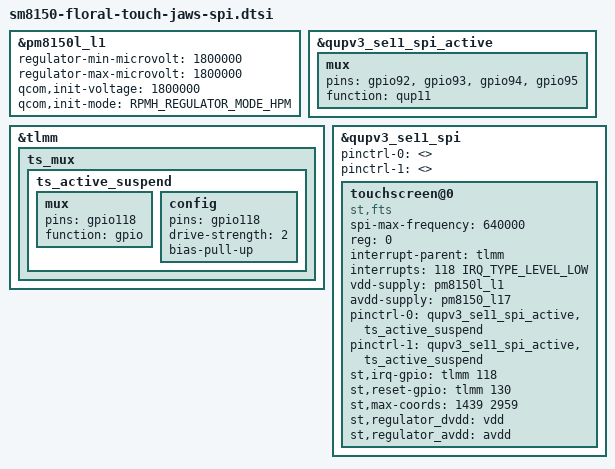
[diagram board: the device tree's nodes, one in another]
/* Copyright (c) 2018, The Linux Foundation. All rights reserved.
 *
 * This program is free software; you can redistribute it and/or modify
 * it under the terms of the GNU General Public License version 2 and
 * only version 2 as published by the Free Software Foundation.
 *
 * This program is distributed in the hope that it will be useful,
 * but WITHOUT ANY WARRANTY; without even the implied warranty of
 * MERCHANTABILITY or FITNESS FOR A PARTICULAR PURPOSE.  See the
 * GNU General Public License for more details.
 */

// Configure 1.8v regulator from fingerprint
&pm8150l_l1 {
	regulator-min-microvolt = <1800000>;
	regulator-max-microvolt = <1800000>;
	qcom,init-voltage = <1800000>;
	qcom,init-mode = <RPMH_REGULATOR_MODE_HPM>;
	status = "okay";
};


/* AP Touch SPI CLK is gpio92, CS is gpio93, MISO is gpio94, MOSI is gpio95.
 * Reset gpio130, interrupt gpio118.
 * (???) bus master switch - gpio??
 */

&qupv3_se11_spi_active {
	mux {
		pins = "gpio92", "gpio93", "gpio94", "gpio95";
		function = "qup11";
	};
};

// Keep interrupt pin active at all times
&tlmm {
	ts_mux {
		ts_active_suspend: ts_active_suspend {
			mux {
				pins = "gpio118";
				function = "gpio";
			};
			config {
				pins = "gpio118";
				drive-strength = <2>;
				bias-pull-up;
			};
		};
	};
};

&qupv3_se11_spi {
	status = "ok";
	pinctrl-0 = <>;
	pinctrl-1 = <>;

	touchscreen@0 {
		status = "ok";
		compatible = "st,fts";
		// TODO: Increase max frequency to ~10-12MHz
		spi-max-frequency = <640000>;

		reg = <0>;
		interrupt-parent = <&tlmm>;
		interrupts = <118 IRQ_TYPE_LEVEL_LOW>;
		vdd-supply = <&pm8150l_l1>;		// Soli's 1.8v pin
		avdd-supply = <&pm8150_l17>;		// Soli's 3.0v pin

		pinctrl-names = "default", "sleep";
		pinctrl-0 = <&qupv3_se11_spi_active &ts_active_suspend>;
		pinctrl-1 = <&qupv3_se11_spi_active &ts_active_suspend>;

		st,irq-gpio = <&tlmm 118 0>;
		st,reset-gpio = <&tlmm 130 0>;
		// TODO: configure switch
		//st,switch_gpio = <&tlmm 136 0>;
		st,max-coords = <1439 2959>;
		st,regulator_dvdd = "vdd";
		st,regulator_avdd = "avdd";
	};
};

